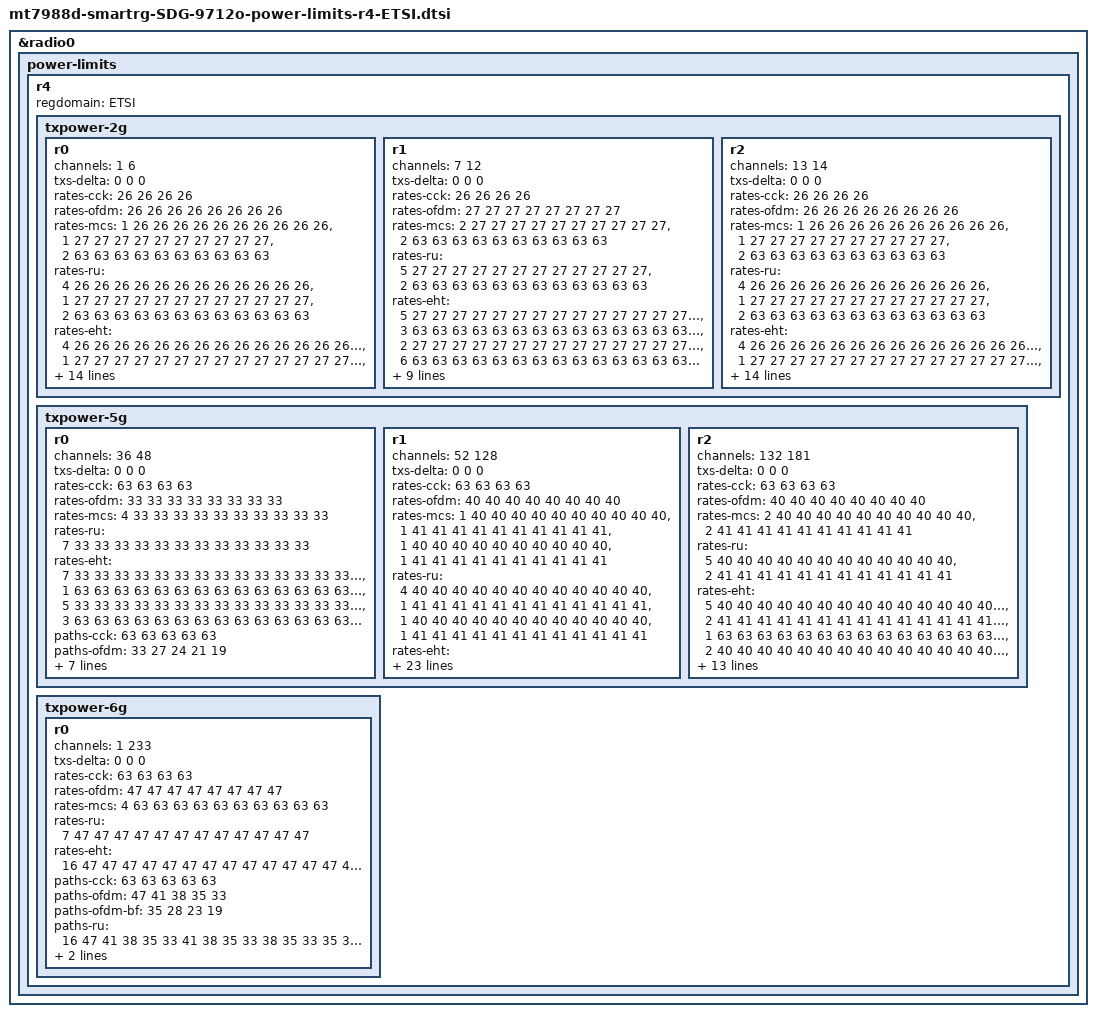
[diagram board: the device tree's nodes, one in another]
// SPDX-License-Identifier: (GPL-2.0 OR MIT)
/*
 * Copyright (C) 2024 SmartRG Inc.
 * Author: Chad Monroe <chad.monroe@smartrg.com>
 */

&radio0 {
	power-limits {
		r4 {
			regdomain = "ETSI";

			txpower-2g {
				r0 {
					channels = <1 6>;
					txs-delta = <0 0 0>;
					rates-cck = <26 26 26 26>;
					rates-ofdm = <26 26 26 26 26 26 26 26>;
					rates-mcs =
					<1 26 26 26 26 26 26 26 26 26 26>,
					<1 27 27 27 27 27 27 27 27 27 27>,
					<2 63 63 63 63 63 63 63 63 63 63>;
					rates-ru =
					<4 26 26 26 26 26 26 26 26 26 26 26 26>,
					<1 27 27 27 27 27 27 27 27 27 27 27 27>,
					<2 63 63 63 63 63 63 63 63 63 63 63 63>;
					rates-eht =
					<4 26 26 26 26 26 26 26 26 26 26 26 26 26 26 26 26>,
					<1 27 27 27 27 27 27 27 27 27 27 27 27 27 27 27 27>,
					<3 63 63 63 63 63 63 63 63 63 63 63 63 63 63 63 63>,
					<2 26 26 26 26 26 26 26 26 26 26 26 26 26 26 26 26>,
					<6 63 63 63 63 63 63 63 63 63 63 63 63 63 63 63 63>;
					paths-cck = <26 20 16 14 12>;
					paths-ofdm = <26 20 16 14 12>;
					paths-ofdm-bf = <14 7 2 0>;
					paths-ru =
					<6 26 20 16 14 12 20 16 14 12 16 14 12 14 12 12>,
					<1 27 21 17 15 13 21 17 15 13 17 15 13 15 13 13>,
					<9 63 63 63 63 63 63 63 63 63 63 63 63 63 63 63>;
					paths-ru-bf =
					<6 26 14 7 2 0 20 13 8 4 16 11 8 14 10 12>,
					<1 27 15 8 3 0 21 14 9 5 17 12 9 15 11 13>,
					<9 63 63 63 63 63 63 63 63 63 63 63 63 63 63 63>;
				};
				r1 {
					channels = <7 12>;
					txs-delta = <0 0 0>;
					rates-cck = <26 26 26 26>;
					rates-ofdm = <27 27 27 27 27 27 27 27>;
					rates-mcs =
					<2 27 27 27 27 27 27 27 27 27 27>,
					<2 63 63 63 63 63 63 63 63 63 63>;
					rates-ru =
					<5 27 27 27 27 27 27 27 27 27 27 27 27>,
					<2 63 63 63 63 63 63 63 63 63 63 63 63>;
					rates-eht =
					<5 27 27 27 27 27 27 27 27 27 27 27 27 27 27 27 27>,
					<3 63 63 63 63 63 63 63 63 63 63 63 63 63 63 63 63>,
					<2 27 27 27 27 27 27 27 27 27 27 27 27 27 27 27 27>,
					<6 63 63 63 63 63 63 63 63 63 63 63 63 63 63 63 63>;
					paths-cck = <26 20 16 14 12>;
					paths-ofdm = <27 21 17 15 13>;
					paths-ofdm-bf = <15 8 3 0>;
					paths-ru =
					<7 27 21 17 15 13 21 17 15 13 17 15 13 15 13 13>,
					<9 63 63 63 63 63 63 63 63 63 63 63 63 63 63 63>;
					paths-ru-bf =
					<7 27 15 8 3 0 21 14 9 5 17 12 9 15 11 13>,
					<9 63 63 63 63 63 63 63 63 63 63 63 63 63 63 63>;
				};
				r2 {
					channels = <13 14>;
					txs-delta = <0 0 0>;
					rates-cck = <26 26 26 26>;
					rates-ofdm = <26 26 26 26 26 26 26 26>;
					rates-mcs =
					<1 26 26 26 26 26 26 26 26 26 26>,
					<1 27 27 27 27 27 27 27 27 27 27>,
					<2 63 63 63 63 63 63 63 63 63 63>;
					rates-ru =
					<4 26 26 26 26 26 26 26 26 26 26 26 26>,
					<1 27 27 27 27 27 27 27 27 27 27 27 27>,
					<2 63 63 63 63 63 63 63 63 63 63 63 63>;
					rates-eht =
					<4 26 26 26 26 26 26 26 26 26 26 26 26 26 26 26 26>,
					<1 27 27 27 27 27 27 27 27 27 27 27 27 27 27 27 27>,
					<3 63 63 63 63 63 63 63 63 63 63 63 63 63 63 63 63>,
					<2 26 26 26 26 26 26 26 26 26 26 26 26 26 26 26 26>,
					<6 63 63 63 63 63 63 63 63 63 63 63 63 63 63 63 63>;
					paths-cck = <26 20 16 14 12>;
					paths-ofdm = <26 20 16 14 12>;
					paths-ofdm-bf = <14 7 2 0>;
					paths-ru =
					<6 26 20 16 14 12 20 16 14 12 16 14 12 14 12 12>,
					<1 27 21 17 15 13 21 17 15 13 17 15 13 15 13 13>,
					<9 63 63 63 63 63 63 63 63 63 63 63 63 63 63 63>;
					paths-ru-bf =
					<6 26 14 7 2 0 20 13 8 4 16 11 8 14 10 12>,
					<1 27 15 8 3 0 21 14 9 5 17 12 9 15 11 13>,
					<9 63 63 63 63 63 63 63 63 63 63 63 63 63 63 63>;
				};
			};
			txpower-5g {
				r0 {
					channels = <36 48>;
					txs-delta = <0 0 0>;
					rates-cck = <63 63 63 63>;
					rates-ofdm = <33 33 33 33 33 33 33 33>;
					rates-mcs =
					<4 33 33 33 33 33 33 33 33 33 33>;
					rates-ru =
					<7 33 33 33 33 33 33 33 33 33 33 33 33>;
					rates-eht =
					<7 33 33 33 33 33 33 33 33 33 33 33 33 33 33 33 33>,
					<1 63 63 63 63 63 63 63 63 63 63 63 63 63 63 63 63>,
					<5 33 33 33 33 33 33 33 33 33 33 33 33 33 33 33 33>,
					<3 63 63 63 63 63 63 63 63 63 63 63 63 63 63 63 63>;
					paths-cck = <63 63 63 63 63>;
					paths-ofdm = <33 27 24 21 19>;
					paths-ofdm-bf = <21 14 9 5>;
					paths-ru =
					<12 33 27 24 21 19 27 24 21 19 24 21 19 21 19 19>,
					<4 63 63 63 63 63 63 63 63 63 63 63 63 63 63 63>;
					paths-ru-bf =
					<12 33 21 14 9 5 27 20 15 11 24 19 15 21 17 19>,
					<4 63 63 63 63 63 63 63 63 63 63 63 63 63 63 63>;
				};
				r1 {
					channels = <52 128>;
					txs-delta = <0 0 0>;
					rates-cck = <63 63 63 63>;
					rates-ofdm = <40 40 40 40 40 40 40 40>;
					rates-mcs =
					<1 40 40 40 40 40 40 40 40 40 40>,
					<1 41 41 41 41 41 41 41 41 41 41>,
					<1 40 40 40 40 40 40 40 40 40 40>,
					<1 41 41 41 41 41 41 41 41 41 41>;
					rates-ru =
					<4 40 40 40 40 40 40 40 40 40 40 40 40>,
					<1 41 41 41 41 41 41 41 41 41 41 41 41>,
					<1 40 40 40 40 40 40 40 40 40 40 40 40>,
					<1 41 41 41 41 41 41 41 41 41 41 41 41>;
					rates-eht =
					<4 40 40 40 40 40 40 40 40 40 40 40 40 40 40 40 40>,
					<1 41 41 41 41 41 41 41 41 41 41 41 41 41 41 41 41>,
					<1 40 40 40 40 40 40 40 40 40 40 40 40 40 40 40 40>,
					<1 41 41 41 41 41 41 41 41 41 41 41 41 41 41 41 41>,
					<1 63 63 63 63 63 63 63 63 63 63 63 63 63 63 63 63>,
					<3 40 40 40 40 40 40 40 40 40 40 40 40 40 40 40 40>,
					<2 41 41 41 41 41 41 41 41 41 41 41 41 41 41 41 41>,
					<3 63 63 63 63 63 63 63 63 63 63 63 63 63 63 63 63>;
					paths-cck = <63 63 63 63 63>;
					paths-ofdm = <40 34 30 28 26>;
					paths-ofdm-bf = <28 21 16 12>;
					paths-ru =
					<6 40 34 30 28 26 34 30 28 26 30 28 26 28 26 26>,
					<1 41 35 31 29 27 35 31 29 27 31 29 27 29 27 27>,
					<2 40 34 30 28 26 34 30 28 26 30 28 26 28 26 26>,
					<3 41 35 31 29 27 35 31 29 27 31 29 27 29 27 27>,
					<4 63 63 63 63 63 63 63 63 63 63 63 63 63 63 63>;
					paths-ru-bf =
					<6 40 28 21 16 12 34 27 22 18 30 25 22 28 24 26>,
					<1 41 29 22 17 13 35 28 23 19 31 26 23 29 25 27>,
					<2 40 28 21 16 12 34 27 22 18 30 25 22 28 24 26>,
					<3 41 29 22 17 13 35 28 23 19 31 26 23 29 25 27>,
					<4 63 63 63 63 63 63 63 63 63 63 63 63 63 63 63>;
				};
				r2 {
					channels = <132 181>;
					txs-delta = <0 0 0>;
					rates-cck = <63 63 63 63>;
					rates-ofdm = <40 40 40 40 40 40 40 40>;
					rates-mcs =
					<2 40 40 40 40 40 40 40 40 40 40>,
					<2 41 41 41 41 41 41 41 41 41 41>;
					rates-ru =
					<5 40 40 40 40 40 40 40 40 40 40 40 40>,
					<2 41 41 41 41 41 41 41 41 41 41 41 41>;
					rates-eht =
					<5 40 40 40 40 40 40 40 40 40 40 40 40 40 40 40 40>,
					<2 41 41 41 41 41 41 41 41 41 41 41 41 41 41 41 41>,
					<1 63 63 63 63 63 63 63 63 63 63 63 63 63 63 63 63>,
					<2 40 40 40 40 40 40 40 40 40 40 40 40 40 40 40 40>,
					<3 41 41 41 41 41 41 41 41 41 41 41 41 41 41 41 41>,
					<3 63 63 63 63 63 63 63 63 63 63 63 63 63 63 63 63>;
					paths-cck = <63 63 63 63 63>;
					paths-ofdm = <40 34 30 28 26>;
					paths-ofdm-bf = <28 21 16 12>;
					paths-ru =
					<7 40 34 30 28 26 34 30 28 26 30 28 26 28 26 26>,
					<5 41 35 31 29 27 35 31 29 27 31 29 27 29 27 27>,
					<4 63 63 63 63 63 63 63 63 63 63 63 63 63 63 63>;
					paths-ru-bf =
					<7 40 28 21 16 12 34 27 22 18 30 25 22 28 24 26>,
					<5 41 29 22 17 13 35 28 23 19 31 26 23 29 25 27>,
					<4 63 63 63 63 63 63 63 63 63 63 63 63 63 63 63>;
				};
			};
			txpower-6g {
				r0 {
					channels = <1 233>;
					txs-delta = <0 0 0>;
					rates-cck = <63 63 63 63>;
					rates-ofdm = <47 47 47 47 47 47 47 47>;
					rates-mcs =
					<4 63 63 63 63 63 63 63 63 63 63>;
					rates-ru =
					<7 47 47 47 47 47 47 47 47 47 47 47 47>;
					rates-eht =
					<16 47 47 47 47 47 47 47 47 47 47 47 47 47 47 47 47>;
					paths-cck = <63 63 63 63 63>;
					paths-ofdm = <47 41 38 35 33>;
					paths-ofdm-bf = <35 28 23 19>;
					paths-ru =
					<16 47 41 38 35 33 41 38 35 33 38 35 33 35 33 33>;
					paths-ru-bf =
					<16 47 35 28 23 19 41 34 29 25 38 33 29 35 31 33>;
				};
			};
		};
	};
};
